# AT32F435 register map
Vendor: Keil; Series: AT32F435; File version: 1.0
CPU: CM4 r0p1, little endian, no MPU, FPU, 4 interrupt priority bits
Registers are 32-bit, read-write, reset 0x0 unless marked. A register's access mark holds for its fields unless they carry their own. Offsets are from the block's base; [hi:lo] are bit positions; {n}, {i} and the like mark numbered series; 'fields as' and 'values as' point back to an identical list.

## ERTC — Real-time clock
Base 0x40002800
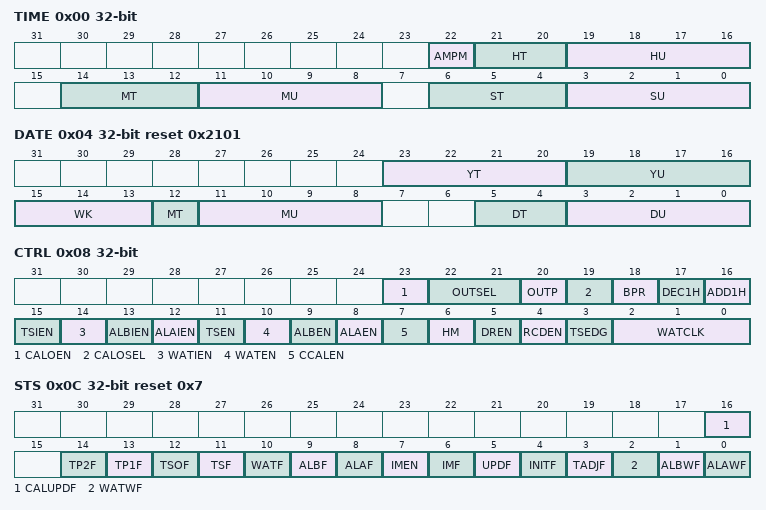
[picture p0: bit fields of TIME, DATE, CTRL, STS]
0x00 TIME
  [22] AMPM — AM/PM notation
    0=AM; 1=PM
  [21:20] HT — Hour tens
  [19:16] HU — Hour units
  [14:12] MT — Minute tens
  [11:8] MU — Minute units
  [6:4] ST — Second tens
  [3:0] SU — Second units
0x04 DATE reset 0x2101
  [23:20] YT — Year tens
  [19:16] YU — Year units
  [15:13] WK — Week
    1=Monday; 2=Tuesday; 3=Wednesday; 4=Thursday; 5=Friday; 6=Saturday; 7=Sunday
  [12] MT — Month tens
  [11:8] MU — Month units
  [5:4] DT — Date tens
  [3:0] DU — Date units
0x08 CTRL — control register
  [23] CALOEN — Calibration output enable
    on read: 0=Disabled (Calibration output is disabled); 1=Enabled (Calibration output is enabled) | on write: 0=Disable (Calibration output disable); 1=Enable (Calibration output enable)
  [22:21] OUTSEL — Output source selection
    0=Disabled; 1=AlarmA (Alarm clock A); 2=AlarmB (Alarm clock B); 3=Wakeup events
  [20] OUTP — Output polarity
    0=High; 1=Low
  [19] CALOSEL — Calibration output selection
    0=Hz512 (512Hz); 1=Hz1 (1Hz)
  [18] BPR — Battery power domain data register
  [17] DEC1H wo write-1-sets — Decrease 1 hour
    1=Sub (Subtract 1 hour)
  [16] ADD1H wo write-1-sets — Add 1 hour
    1=Add (Add 1 hour)
  [15] TSIEN — Timestamp interrupt enable
    on read: 0=Disabled (Timestamp interrupt is disabled); 1=Enabled (Timestamp interrupt is enabled) | on write: 0=Disable (Timestamp interrupt disable); 1=Enable (Timestamp interrupt enable)
  [14] WATIEN — Wakeup timer interrupt enable
    on read: 0=Disabled (Wakeup timer interrupt is disabled); 1=Enabled (Wakeup timer interrupt is enabled) | on write: 0=Disable (Wakeup timer interrupt disable); 1=Enable (Wakeup timer interrupt enable)
  [13] ALBIEN — Alarm B interrupt enable
    on read: 0=Disabled (Alarm interrupt is disabled); 1=Enabled (Alarm interrupt is enabled) | on write: 0=Disable (Alarm interrupt disable); 1=Enable (Alarm interrupt enable)
  [12] ALAIEN — Alarm A interrupt enable
    values as ALBIEN
  [11] TSEN — Timestamp enable
    on read: 0=Disabled (Timestamp is disabled); 1=Enabled (Timestamp is enabled) | on write: 0=Disable (Timestamp disable); 1=Enable (Timestamp enable)
  [10] WATEN — Wakeup timer enable
    on read: 0=Disabled (Wakeup timer is disabled); 1=Enabled (Wakeup timer is enabled) | on write: 0=Disable (Wakeup timer disable); 1=Enable (Wakeup timer enable)
  [9] ALBEN — Alarm B enable
    on read: 0=Disabled (Alarm is disabled); 1=Enabled (Alarm is enabled) | on write: 0=Disable (Alarm disable); 1=Enable (Alarm enable)
  [8] ALAEN — Alarm A enable
    values as ALBEN
  [7] CCALEN — Coarse calibration enable
    on read: 0=Disabled (Coarse calibration is disabled); 1=Enabled (Coarse calibration is enabled) | on write: 0=Disable (Coarse calibration disable); 1=Enable (Coarse calibration enable)
  [6] HM — Hour mode
    0=Hour24 (24-hour format); 1=Hour12 (12-hour format)
  [5] DREN — Date/time register direct read enable
    on read: 0=Disabled (Date/time register direct read is disabled); 1=Enabled (Date/time register direct read is enabled) | on write: 0=Disable (Date/time register direct read disable); 1=Enable (Date/time register direct read enable)
  [4] RCDEN — Reference clock detection enable
    on read: 0=Disabled (Reference clock detection is disabled); 1=Enabled (Reference clock detection is enabled) | on write: 0=Disable (Reference clock detection disable); 1=Enable (Reference clock detection enable)
  [3] TSEDG — Timestamp trigger edge
    0=Rising edge; 1=Falling edge
  [2:0] WATCLK — Wakeup timer clock selection
    0=ertc_clk_div16 (ERTC_CLK/16); 1=ertc_clk_div8 (ERTC_CLK/8); 2=ertc_clk_div4 (ERTC_CLK/4); 3=ertc_clk_div2 (ERTC_CLK/2); 4=ck_b; 6=ck_b_plus_2_16 (ck_b is selected. 2^16 is added to the wakeup counter value, and wakeup time =ERTC_WAT+2^16.)
0x0C STS reset 0x7 — initialization and status register
  [16] CALUPDF ro — Calibration value update completed flag
  [14] TP2F write-0-clears — Tamper detection 2 flag
  [13] TP1F write-0-clears — Tamper detection 1 flag
  [12] TSOF write-0-clears — Timestamp overflow flag
  [11] TSF write-0-clears — Timestamp flag
  [10] WATF write-0-clears — Wakeup timer flag
  [9] ALBF write-0-clears — Alarm B flag
  [8] ALAF write-0-clears — Alarm A flag
  [7] IMEN — Initialization mode enable
  [6] IMF ro — Enter initialization mode flag
  [5] UPDF write-0-clears — Calendar update flag
  [4] INITF ro — Calendar initialization flag
  [3] TADJF ro — Time adjustment flag
  [2] WATWF ro — Wakeup timer register allows write flag
  [1] ALBWF ro — Alarm B register allows write flag
  [0] ALAWF ro — Alarm A register allows write flag
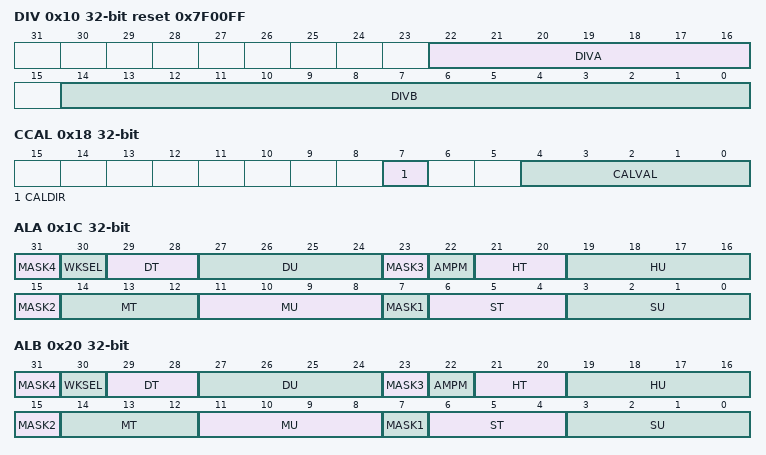
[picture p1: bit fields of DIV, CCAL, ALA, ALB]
0x10 DIV reset 0x7F00FF — Divider register
  [22:16] DIVA — Divider A
  [14:0] DIVB range 0..2047 — Divider B
0x14 WAT reset 0xFFFF — Wakeup timer register
  [15:0] VAL — Wakeup timer reload value
0x18 CCAL — Calibration register
  [7] CALDIR — Calibration direction
    0=Pos (Positive calibration (+0, +4, +8...)); 1=Neg (Negative calibration (-0, -2, -4...))
  [4:0] CALVAL — Calibration value
0x1C ALA — Alarm A register
  [31] MASK4 — Date/week mask
    0=NoMask (Date/week day is not masked); 1=Mask (Alarm clock doesn't care about date/week day)
  [30] WKSEL — Date/week mode select
    0=Date; 1=WeekDay
  [29:28] DT — Date tens
  [27:24] DU — Date units
  [23] MASK3 — Hours mask
    0=NoMask (No hour mask); 1=Mask (Alarm clock doesn't care about hours)
  [22] AMPM
    0=AM; 1=PM
  [21:20] HT — Hour tens
  [19:16] HU — Hour units
  [15] MASK2 — Minutes mask
    0=NoMask (No minute mask); 1=Mask (Alarm clock doesn't care about minutes)
  [14:12] MT — Minute tens
  [11:8] MU — Minute units
  [7] MASK1 — Seconds mask
    0=NoMask (No second mask); 1=Mask (Alarm clock doesn't care about seconds)
  [6:4] ST — Second tens
  [3:0] SU — Second units
0x20 ALB — Alarm B register
  fields as ALA
0x24 WP wo — write protection register
  [7:0] CMD — Command register
    0=Invalid (Write value 0x00 which is considered invalid and will activate write protection back); 83=Key2 (Unlock key 2); 202=Key1 (Unlock key 1)
0x28 SBS ro — sub second register
  [15:0] SBS — Subsecond is the value in the DIVB counter. Clock frequency = ERTC_CLK/(DIVA+1)
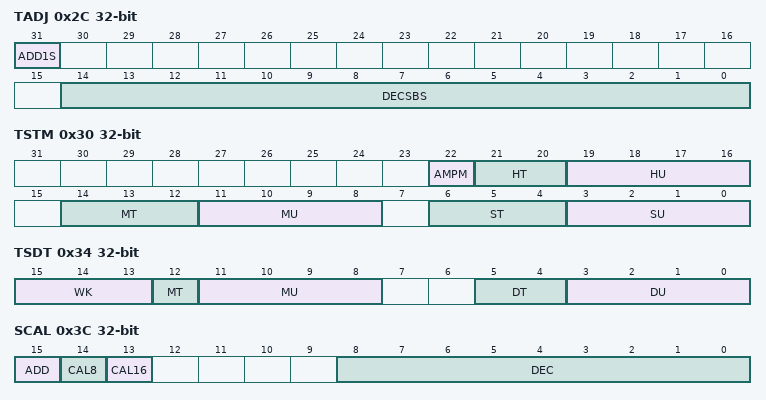
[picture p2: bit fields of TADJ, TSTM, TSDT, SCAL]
0x2C TADJ wo — time adjust register
  [31] ADD1S — Add 1 second. This bit can be written only when TADJF=0. It is intended to be used with DECSBS in order to fine-tune the time
    0=NoEffect; 1=AddOneSecond
  [14:0] DECSBS — Decrease sub-second value. Delay (ADD1S=0): Delay = DECSBS/(DIVB+1). Advance (ADD1S=1) : Advance =1-(DECSBS/(DIVB+1))
0x30 TSTM ro — time stamp time register
  [22] AMPM
    0=AM; 1=PM
  [21:20] HT — Hour tens
  [19:16] HU — Hour units
  [14:12] MT — Minute tens
  [11:8] MU — Minute units
  [6:4] ST — Second tens
  [3:0] SU — Second units
0x34 TSDT ro — timestamp date register
  [15:13] WK — Week
    values as DATE.WK
  [12] MT — Month tens
  [11:8] MU — Month units
  [5:4] DT — Date tens
  [3:0] DU — Date units
0x38 TSSBS ro — timestamp sub second register
  [15:0] SBS range 0..255 — Sub second value
0x3C SCAL — calibration register
  [15] ADD — Add ERTC clock
    0=None (No effect); 1=OneClkEvery2_11Cycles (One ERTC_CLK is inserted every 2^11 ERTC_CLK cycles)
  [14] CAL8 — 8-second calibration period
    0=None (No effect); 1=Period8Seconds (8-second calibration)
  [13] CAL16 — 16 second calibration period
    0=None (No effect); 1=Period16Seconds (16-second calibration)
  [8:0] DEC range 0..31 — Decrease ERTC clock
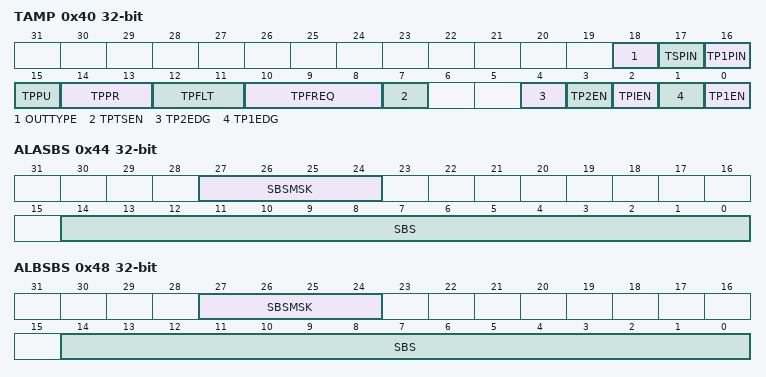
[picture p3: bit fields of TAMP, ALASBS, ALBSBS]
0x40 TAMP — tamper and alternate function configuration register
  [18] OUTTYPE — Output type
    0=OpenDrain; 1=PushPull
  [17] TSPIN — Time stamp detection pin selection
    0=ErtcMux1; 1=ErtcMux2
  [16] TP1PIN — Tamper detection pin selection
    0=ErtcMux1; 1=ErtcMux2
  [15] TPPU — Tamper detection pull-up
    0=Enabled (Tamper detection pull-up enabled); 1=Disabled (Tamper detection pull-up disabled)
  [14:13] TPPR — Tamper detection pre-charge time
    0=Cyc1 (1 ERTC_CLK cycle); 1=Cyc2 (2 ERTC_CLK cycles); 2=Cyc4 (4 ERTC_CLK cycles); 3=Cyc8 (8 ERTC_CLK cycles)
  [12:11] TPFLT — Tamper detection filter time
    0=NoFilter; 1=Filter2 (Tamper is detected after 2 consecutive samples); 2=Filter4 (Tamper is detected after 4 consecutive samples); 3=Filter8 (Tamper is detected after 8 consecutive samples)
  [10:8] TPFREQ — Tamper detection frequency
    0=Div32768 (ERTC_CLK/32768); 1=Div16384 (ERTC_CLK/16384); 2=Div8192 (ERTC_CLK/8192); 3=Div4096 (ERTC_CLK/4096); 4=Div2048 (ERTC_CLK/2048); 5=Div1024 (ERTC_CLK/1024); 6=Div512 (ERTC_CLK/512); 7=Div256 (ERTC_CLK/256)
  [7] TPTSEN — Tamper detection timestamp enable
    0=Disabled (Tamper detection timestamp disabled); 1=Enabled (Tamper detection timestamp enabled)
  [4] TP2EDG — Tamper detection 2 valid edge
    0=RisingOrLow (If TPFLT=0: Rising edge. If TPFLT>0: low level); 1=FallingOrHigh (If TPFLT=0: Falling edge. If TPFLT>0: High level)
  [3] TP2EN — Tamper detection 2 enable
    0=Disabled (Tamper detection disabled); 1=Enabled (Tamper detection enabled)
  [2] TPIEN — Tamper detection interrupt enable
    0=Disabled (Tamper interrupt disabled); 1=Enabled (Tamper interrupt enabled)
  [1] TP1EDG — Tamper detection 1 valid edge
    values as TP2EDG
  [0] TP1EN — Tamper detection 1 enable
    values as TP2EN
0x44 ALASBS — alarm A sub second register
  [27:24] SBSMSK — Sub-second mask
  [14:0] SBS range 0..127 — Sub-seconds value
0x48 ALBSBS — alarm B sub second register
  fields as ALASBS
{0x4C+4i} BPR{i}DT (i=1..20) — Battery powered domain register
